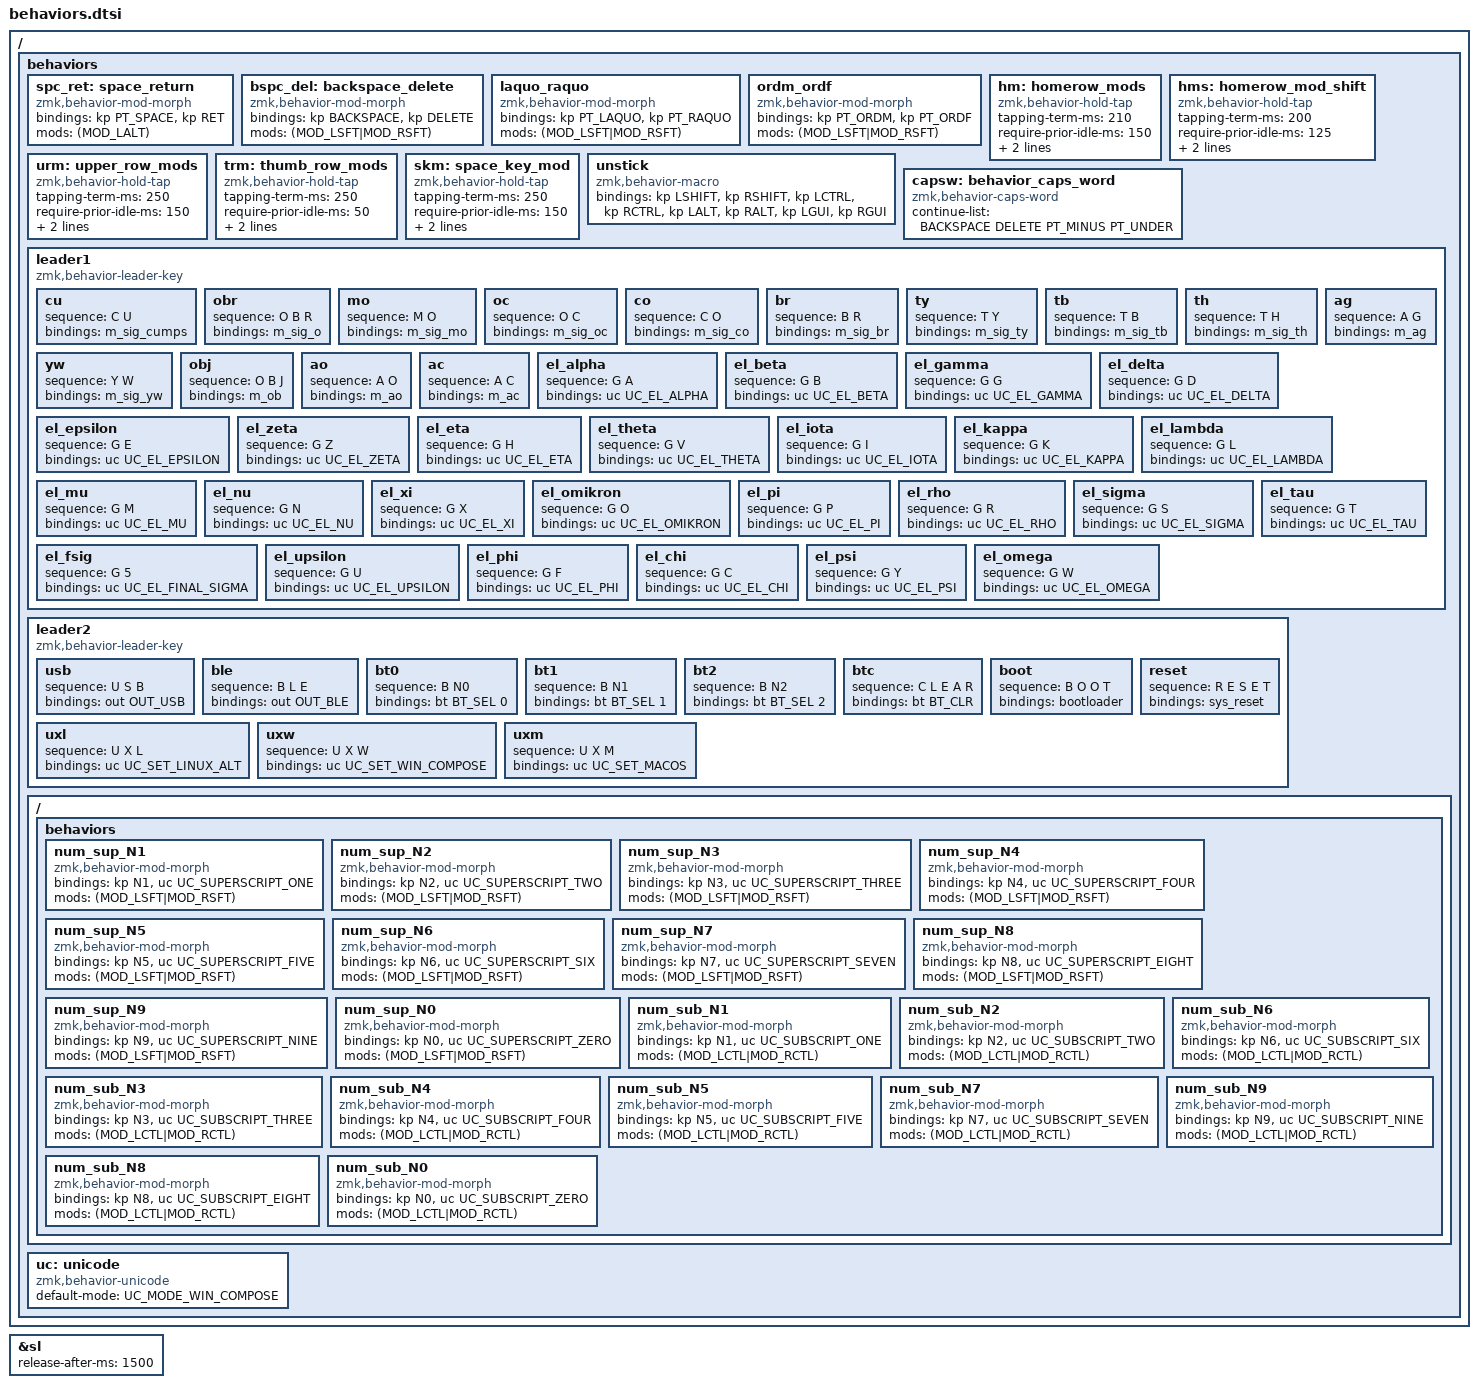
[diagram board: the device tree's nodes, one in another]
// Custom behaviours, hold-taps and the sticky-layer override.

// Upper row mods macro
#define URML(k1,k2,k3,k4,k5) &urm BLUETH k1  &urm MACROS k2  &urm MSOUTL k3  &urm WMCFG  k4  &urm MEDIA k5
#define URMR(k1,k2,k3,k4,k5) &urm MEDIA k1  &urm WMCFG  k2  &urm MSOUTL k3  &urm MACROS k4  &urm BLUETH k5
// Home row mods macro
#define HRML(k1,k2,k3,k4) &hm LGUI   k1  &hm LCTRL k2  &hm LALT  k3  &hms LSHIFT k4
#define HRMR(k1,k2,k3,k4) &hms RSHIFT k1  &hm LALT  k2  &hm LCTRL k3  &hm RGUI   k4
// Lower row mods macro
#define LRML(k1,k2,k3,k4) &kp k1  &hm RCTRL k2  &hm RALT  k3  &kp k4
#define LRMR(k1,k2,k3,k4) &kp k1  &hm RALT  k2  &hm RCTRL k3  &hm K_CMENU k4

&sl {
    release-after-ms = <1500>;
};


/ {
    behaviors {
        spc_ret: space_return {
            compatible = "zmk,behavior-mod-morph";
            #binding-cells = <0>;
            bindings = <&kp PT_SPACE>, <&kp RET>;
            mods = <(MOD_LALT)>;
        };
        bspc_del: backspace_delete {
            compatible = "zmk,behavior-mod-morph";
            #binding-cells = <0>;
            bindings = <&kp BACKSPACE>, <&kp DELETE>;
            mods = <(MOD_LSFT|MOD_RSFT)>;
            /*keep-mods = <(MOD_RSFT)>;*/
        };
        laquo_raquo: laquo_raquo {
            compatible = "zmk,behavior-mod-morph";
            #binding-cells = <0>;
            bindings = <&kp PT_LAQUO>, <&kp PT_RAQUO>;
            mods = <(MOD_LSFT|MOD_RSFT)>;
        };
        ordm_ordf: ordm_ordf {
            compatible = "zmk,behavior-mod-morph";
            #binding-cells = <0>;
            bindings = <&kp PT_ORDM>, <&kp PT_ORDF>;
            mods = <(MOD_LSFT|MOD_RSFT)>;
        };
        hm: homerow_mods {
            compatible = "zmk,behavior-hold-tap";
            #binding-cells = <2>;
            tapping-term-ms = <210>;
            require-prior-idle-ms = <150>;
            flavor = "tap-preferred";
            bindings = <&kp>, <&kp>;
        };
        hms: homerow_mod_shift {
            compatible = "zmk,behavior-hold-tap";
            #binding-cells = <2>;
            tapping-term-ms = <200>;
            require-prior-idle-ms = <125>;
            flavor = "balanced";
            bindings = <&kp>, <&kp>;
        };
        urm: upper_row_mods {
            compatible = "zmk,behavior-hold-tap";
            #binding-cells = <2>;
            tapping-term-ms = <250>;
            require-prior-idle-ms = <150>;
            flavor = "tap-preferred";
            bindings = <&mo>, <&kp>;
        };
        trm: thumb_row_mods {
            compatible = "zmk,behavior-hold-tap";
            #binding-cells = <2>;
            tapping-term-ms = <250>;
            require-prior-idle-ms = <50>;
            flavor = "tap-preferred";
            bindings = <&mo>, <&kp>;
         };
         skm: space_key_mod {  //TODO(heiko): not yet used
            compatible = "zmk,behavior-hold-tap";
            #binding-cells = <2>;
            tapping-term-ms = <250>;
            require-prior-idle-ms = <150>;
            flavor = "tap-preferred";
            /*bindings = <&mo>, <&spc_ret>;*/
            bindings = <&mo>, <&kp>;
        };
        unstick: unstick {
            compatible = "zmk,behavior-macro";
            #binding-cells = <0>;
            bindings = <&kp LSHIFT &kp RSHIFT &kp LCTRL &kp RCTRL &kp LALT &kp RALT &kp LGUI &kp RGUI>;
        };
        capsw: behavior_caps_word {
            compatible = "zmk,behavior-caps-word";
            #binding-cells = <0>;
            continue-list = <BACKSPACE DELETE PT_MINUS PT_UNDER>;
        };
        // Leader key instances.
        //
        // leader1 is reached from the outermost left thumb on the 36-key boards
        // (LH2) and, on the 34-key sweep which has no LH2, from the LM4 LM3 LM2
        // chord - see combos.dtsi.
        // leader2 is reached from the N+M combo on every board.
        //
        // leader1 = the AHK replacement sequences (previously typed as "]xx").
        //           The leader key itself replaces the "]" prefix, so "]c"
        //           becomes leader1 then C.
        leader1: leader1 {
            compatible = "zmk,behavior-leader-key";
            #binding-cells = <0>;
            // Portuguese / English sign-offs
            cu  { sequence = <C U>;   bindings = <&m_sig_cumps>; };
            obr { sequence = <O B R>; bindings = <&m_sig_o>; };
            mo  { sequence = <M O>;   bindings = <&m_sig_mo>; };
            oc  { sequence = <O C>;   bindings = <&m_sig_oc>; };
            co  { sequence = <C O>;   bindings = <&m_sig_co>; };
            br  { sequence = <B R>;   bindings = <&m_sig_br>; };
            ty  { sequence = <T Y>;   bindings = <&m_sig_ty>; };
            tb  { sequence = <T B>;   bindings = <&m_sig_tb>; };
            th  { sequence = <T H>;   bindings = <&m_sig_th>; };
            yw  { sequence = <Y W>;   bindings = <&m_sig_yw>; };
            // MS Outlook headings (AHK "^b" = Ctrl-B)
            ag  { sequence = <A G>;   bindings = <&m_ag>; };
            obj { sequence = <O B J>; bindings = <&m_ob>; };
            ao  { sequence = <A O>;   bindings = <&m_ao>; };
            ac  { sequence = <A C>;   bindings = <&m_ac>; };

            // Greek letters, typed via the zmk-unicode module: G then the
            // letter the name starts with (G A = alpha, G B = beta, ...).
            // Uppercase variants come from Shift, as with any UC_* alias.
            //
            // These are prefixed G rather than urob's E, so they cannot collide
            // with the two-letter mnemonics above (nothing here starts with G).
            // Adapted from urob/zmk-config config/leader.dtsi.
            el_alpha   { sequence = <G A>; bindings = <&uc UC_EL_ALPHA>; };
            el_beta    { sequence = <G B>; bindings = <&uc UC_EL_BETA>; };
            el_gamma   { sequence = <G G>; bindings = <&uc UC_EL_GAMMA>; };
            el_delta   { sequence = <G D>; bindings = <&uc UC_EL_DELTA>; };
            el_epsilon { sequence = <G E>; bindings = <&uc UC_EL_EPSILON>; };
            el_zeta    { sequence = <G Z>; bindings = <&uc UC_EL_ZETA>; };
            el_eta     { sequence = <G H>; bindings = <&uc UC_EL_ETA>; };
            el_theta   { sequence = <G V>; bindings = <&uc UC_EL_THETA>; };
            el_iota    { sequence = <G I>; bindings = <&uc UC_EL_IOTA>; };
            el_kappa   { sequence = <G K>; bindings = <&uc UC_EL_KAPPA>; };
            el_lambda  { sequence = <G L>; bindings = <&uc UC_EL_LAMBDA>; };
            el_mu      { sequence = <G M>; bindings = <&uc UC_EL_MU>; };
            el_nu      { sequence = <G N>; bindings = <&uc UC_EL_NU>; };
            el_xi      { sequence = <G X>; bindings = <&uc UC_EL_XI>; };
            el_omikron { sequence = <G O>; bindings = <&uc UC_EL_OMIKRON>; };
            el_pi      { sequence = <G P>; bindings = <&uc UC_EL_PI>; };
            el_rho     { sequence = <G R>; bindings = <&uc UC_EL_RHO>; };
            el_sigma   { sequence = <G S>; bindings = <&uc UC_EL_SIGMA>; };
            el_fsig    { sequence = <G 5>; bindings = <&uc UC_EL_FINAL_SIGMA>; };  // ς, word-final
            el_tau     { sequence = <G T>; bindings = <&uc UC_EL_TAU>; };
            el_upsilon { sequence = <G U>; bindings = <&uc UC_EL_UPSILON>; };
            el_phi     { sequence = <G F>; bindings = <&uc UC_EL_PHI>; };
            el_chi     { sequence = <G C>; bindings = <&uc UC_EL_CHI>; };
            el_psi     { sequence = <G Y>; bindings = <&uc UC_EL_PSI>; };
            el_omega   { sequence = <G W>; bindings = <&uc UC_EL_OMEGA>; };
        };

        // leader2 = system / bluetooth sequences.
        leader2: leader2 {
            compatible = "zmk,behavior-leader-key";
            #binding-cells = <0>;
            usb { sequence = <U S B>; bindings = <&out OUT_USB>; };
            ble { sequence = <B L E>; bindings = <&out OUT_BLE>; };
            bt0 { sequence = <B N0>; bindings = <&bt BT_SEL 0>; };
            bt1 { sequence = <B N1>; bindings = <&bt BT_SEL 1>; };
            bt2 { sequence = <B N2>; bindings = <&bt BT_SEL 2>; };
            btc { sequence = <C L E A R>; bindings = <&bt BT_CLR>; };
            boot { sequence = <B O O T>; bindings = <&bootloader>; };
            reset { sequence = <R E S E T>; bindings = <&sys_reset>; };

            // Unicode input mode. Each OS enters code points differently, and
            // the mode is a runtime property of the &uc behavior, so it can be
            // switched here without reflashing. The default is set below the
            // root node; these sequences override it until the next reset.
            //
            // The BLUETH layer also sets the mode when you pick a Bluetooth
            // profile, which is the usual way to switch - see macros.dtsi.
            //
            //   UXL = Linux / fcitx5
            //   UXW = Windows (needs WinCompose installed)
            //   UXM = macOS
            uxl { sequence = <U X L>; bindings = <&uc UC_SET_LINUX_ALT>; };
            uxw { sequence = <U X W>; bindings = <&uc UC_SET_WIN_COMPOSE>; };
            uxm { sequence = <U X M>; bindings = <&uc UC_SET_MACOS>; };
        };


        /*
         * Superscripts and subscripts on the NUMNAV digit keys.
         *
         * A mod-morph is the only mechanism that can see shift: combos match
         * physical key positions and have no notion of modifiers. Each NUMNAV
         * digit therefore becomes a morph rather than a plain &kp:
         *
         *     Shift + digit  -> superscript   2 -> 2
         *     Ctrl  + digit  -> subscript     2 -> 2
         *     digit alone    -> plain digit   (unchanged)
         *
         * The morph consumes its modifier, which is why the modifier must mean
         * nothing else on this layer - on NUMNAV the digits carry no shifted or
         * ctrl-modified meaning, so nothing is lost. QWERTY is untouched, so
         * Shift+2 there still types an ordinary shifted 2.
         *
         * Note superscript 1, 2 and 3 are U+00B9/B2/B3 from latin_1_supplement,
         * while 0 and 4..9 are U+2070/2074..2079 from
         * superscripts_and_subscripts - see the includes in keys.h.
         *
         * Written with zmk-helpers' ZMK_MOD_MORPH, which emits the same
         * compatible/#binding-cells pair the hand-written morphs above use.
         */
        ZMK_MOD_MORPH(num_sup_N1, bindings = <&kp N1 &uc UC_SUPERSCRIPT_ONE>; mods = <(MOD_LSFT|MOD_RSFT)>;)
        ZMK_MOD_MORPH(num_sup_N2, bindings = <&kp N2 &uc UC_SUPERSCRIPT_TWO>; mods = <(MOD_LSFT|MOD_RSFT)>;)
        ZMK_MOD_MORPH(num_sup_N3, bindings = <&kp N3 &uc UC_SUPERSCRIPT_THREE>; mods = <(MOD_LSFT|MOD_RSFT)>;)
        ZMK_MOD_MORPH(num_sup_N4, bindings = <&kp N4 &uc UC_SUPERSCRIPT_FOUR>; mods = <(MOD_LSFT|MOD_RSFT)>;)
        ZMK_MOD_MORPH(num_sup_N5, bindings = <&kp N5 &uc UC_SUPERSCRIPT_FIVE>; mods = <(MOD_LSFT|MOD_RSFT)>;)
        ZMK_MOD_MORPH(num_sup_N6, bindings = <&kp N6 &uc UC_SUPERSCRIPT_SIX>; mods = <(MOD_LSFT|MOD_RSFT)>;)
        ZMK_MOD_MORPH(num_sup_N7, bindings = <&kp N7 &uc UC_SUPERSCRIPT_SEVEN>; mods = <(MOD_LSFT|MOD_RSFT)>;)
        ZMK_MOD_MORPH(num_sup_N8, bindings = <&kp N8 &uc UC_SUPERSCRIPT_EIGHT>; mods = <(MOD_LSFT|MOD_RSFT)>;)
        ZMK_MOD_MORPH(num_sup_N9, bindings = <&kp N9 &uc UC_SUPERSCRIPT_NINE>; mods = <(MOD_LSFT|MOD_RSFT)>;)
        ZMK_MOD_MORPH(num_sup_N0, bindings = <&kp N0 &uc UC_SUPERSCRIPT_ZERO>; mods = <(MOD_LSFT|MOD_RSFT)>;)

        ZMK_MOD_MORPH(num_sub_N1, bindings = <&kp N1 &uc UC_SUBSCRIPT_ONE>; mods = <(MOD_LCTL|MOD_RCTL)>;)
        ZMK_MOD_MORPH(num_sub_N2, bindings = <&kp N2 &uc UC_SUBSCRIPT_TWO>; mods = <(MOD_LCTL|MOD_RCTL)>;)
        ZMK_MOD_MORPH(num_sub_N3, bindings = <&kp N3 &uc UC_SUBSCRIPT_THREE>; mods = <(MOD_LCTL|MOD_RCTL)>;)
        ZMK_MOD_MORPH(num_sub_N4, bindings = <&kp N4 &uc UC_SUBSCRIPT_FOUR>; mods = <(MOD_LCTL|MOD_RCTL)>;)
        ZMK_MOD_MORPH(num_sub_N5, bindings = <&kp N5 &uc UC_SUBSCRIPT_FIVE>; mods = <(MOD_LCTL|MOD_RCTL)>;)
        ZMK_MOD_MORPH(num_sub_N6, bindings = <&kp N6 &uc UC_SUBSCRIPT_SIX>; mods = <(MOD_LCTL|MOD_RCTL)>;)
        ZMK_MOD_MORPH(num_sub_N7, bindings = <&kp N7 &uc UC_SUBSCRIPT_SEVEN>; mods = <(MOD_LCTL|MOD_RCTL)>;)
        ZMK_MOD_MORPH(num_sub_N8, bindings = <&kp N8 &uc UC_SUBSCRIPT_EIGHT>; mods = <(MOD_LCTL|MOD_RCTL)>;)
        ZMK_MOD_MORPH(num_sub_N9, bindings = <&kp N9 &uc UC_SUBSCRIPT_NINE>; mods = <(MOD_LCTL|MOD_RCTL)>;)
        ZMK_MOD_MORPH(num_sub_N0, bindings = <&kp N0 &uc UC_SUBSCRIPT_ZERO>; mods = <(MOD_LCTL|MOD_RCTL)>;)

        /* Unicode input defaults to Windows (WinCompose). Picking a Bluetooth
         * profile on the BLUETH layer switches this to match the machine, and
         * the UXL/UXW/UXM leader sequences override it manually. */
        uc: unicode {
            compatible = "zmk,behavior-unicode";
            #binding-cells = <2>;
            default-mode = <UC_MODE_WIN_COMPOSE>;
        };
    };
};
